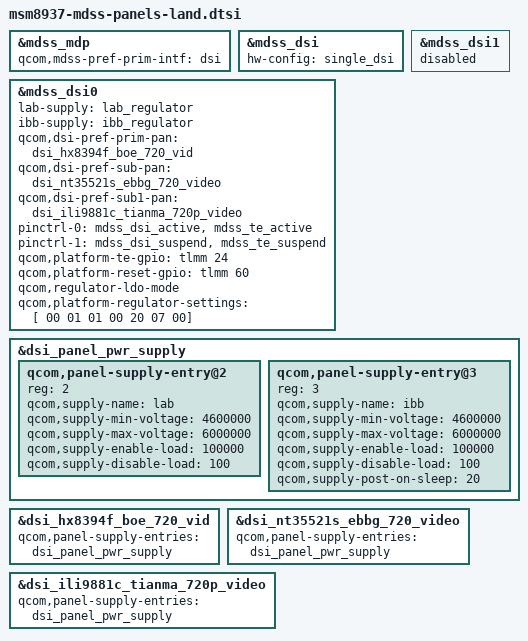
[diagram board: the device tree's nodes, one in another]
/*
 * Copyright (c) 2015, The Linux Foundation. All rights reserved.
 *
 * This program is free software; you can redistribute it and/or modify
 * it under the terms of the GNU General Public License version 2 and
 * only version 2 as published by the Free Software Foundation.
 *
 * This program is distributed in the hope that it will be useful,
 * but WITHOUT ANY WARRANTY; without even the implied warranty of
 * MERCHANTABILITY or FITNESS FOR A PARTICULAR PURPOSE.  See the
 * GNU General Public License for more details.
 */

#include "../msm8937-mdss-panels.dtsi"
#include "dsi-panel-hx8394f-boe-720p-video.dtsi"
#include "dsi-panel-nt35521s-ebbg-720p-video.dtsi"
#include "dsi-panel-ili9881c-tianma-720p-video.dtsi"

&mdss_mdp {
	qcom,mdss-pref-prim-intf = "dsi";
};

&mdss_dsi {
	hw-config = "single_dsi";
};

&mdss_dsi0 {
	lab-supply = <&lab_regulator>;
	ibb-supply = <&ibb_regulator>;

	qcom,dsi-pref-prim-pan = <&dsi_hx8394f_boe_720_vid>;
	qcom,dsi-pref-sub-pan = <&dsi_nt35521s_ebbg_720_video>;
	qcom,dsi-pref-sub1-pan = <&dsi_ili9881c_tianma_720p_video>;
	pinctrl-names = "mdss_default", "mdss_sleep";
	pinctrl-0 = <&mdss_dsi_active &mdss_te_active>;
	pinctrl-1 = <&mdss_dsi_suspend &mdss_te_suspend>;

	qcom,platform-te-gpio = <&tlmm 24 0>;
	qcom,platform-reset-gpio = <&tlmm 60 0>;

	qcom,regulator-ldo-mode;
	qcom,platform-regulator-settings = [ 00 01 01 00 20 07 00];

};

&mdss_dsi1 {
	status = "disabled";
};

&dsi_panel_pwr_supply {
	qcom,panel-supply-entry@2 {
		reg = <2>;
		qcom,supply-name = "lab";
		qcom,supply-min-voltage = <4600000>;
		qcom,supply-max-voltage = <6000000>;
		qcom,supply-enable-load = <100000>;
		qcom,supply-disable-load = <100>;
	};

	qcom,panel-supply-entry@3 {
		reg = <3>;
		qcom,supply-name = "ibb";
		qcom,supply-min-voltage = <4600000>;
		qcom,supply-max-voltage = <6000000>;
		qcom,supply-enable-load = <100000>;
		qcom,supply-disable-load = <100>;
		qcom,supply-post-on-sleep = <20>;
	};
};

&dsi_hx8394f_boe_720_vid {
	qcom,panel-supply-entries = <&dsi_panel_pwr_supply>;
};

&dsi_nt35521s_ebbg_720_video {
	qcom,panel-supply-entries = <&dsi_panel_pwr_supply>;
};

&dsi_ili9881c_tianma_720p_video {
	qcom,panel-supply-entries = <&dsi_panel_pwr_supply>;
};
